# SF32LB56x register map
File version: 1.0
CPU: CM33 r0p1, little endian, MPU, FPU, 3 interrupt priority bits
Registers are 32-bit, read-write, reset 0x0 unless marked. A register's access mark holds for its fields unless they carry their own. Offsets are from the block's base; [hi:lo] are bit positions; {n}, {i} and the like mark numbered series; 'fields as' and 'values as' point back to an identical list.

## GPADC
Base 0x50016000
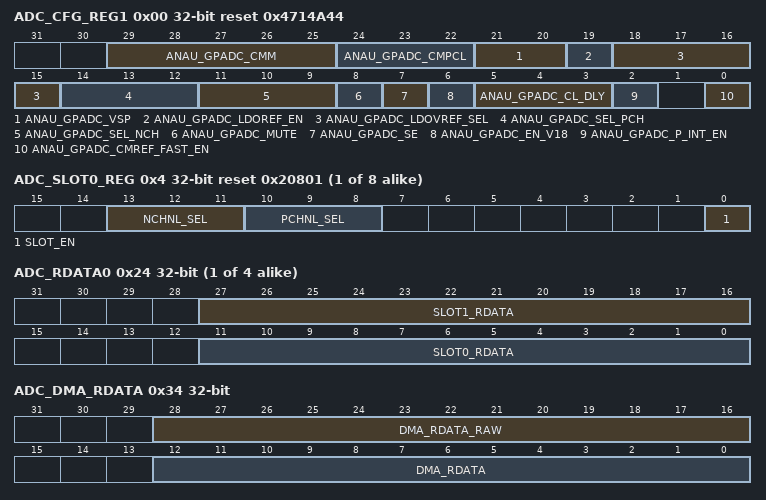
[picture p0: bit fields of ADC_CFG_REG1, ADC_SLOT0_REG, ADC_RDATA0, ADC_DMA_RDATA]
0x00 ADC_CFG_REG1 reset 0x4714A44 — ADC Analog Config Register 1
  [29:25] ANAU_GPADC_CMM — Tune CDAC CM voltage 375mV range (increasing) / 25mV step, 8: for 0.5V Vcm,in
  [24:22] ANAU_GPADC_CMPCL — Tune ADC comparator CL= 3: 40f, range: 10fF (0) ~ 80fF (7) / 10fF step
  [21:20] ANAU_GPADC_VSP — Set comparator input CM in sampling phase, 0.539V (0) / 0.578V (1) / 0.642V (2) / 0.784V (3)
  [19] ANAU_GPADC_LDOREF_EN — Enable LDORF for ADC VREF
  [18:15] ANAU_GPADC_LDOVREF_SEL — Set reference voltage for LDOREF, range = 0.35V(0) ~ 0.65V(15), step = 20mV
  [14:12] ANAU_GPADC_SEL_PCH — Select P-side input channel for GPADC, 0 for channel 0, 7 for channel 7, effective when force on
  [11:9] ANAU_GPADC_SEL_NCH — Select N-side input channel for GPADC, 0 for channel 0, 7 for channel 7, effective when force on
  [8] ANAU_GPADC_MUTE — Short GPADC P and N input to CMREF, i.e., VREF/2
  [7] ANAU_GPADC_SE — Set GPADC in single-ended mode, signal range at P-input: 0 ~ VREF
  [6] ANAU_GPADC_EN_V18
  [5:3] ANAU_GPADC_CL_DLY
  [2] ANAU_GPADC_P_INT_EN
  [0] ANAU_GPADC_CMREF_FAST_EN
{0x4+4i} ADC_SLOT{i}_REG reset 0x20801 (i=0..7) — ADC Slot{i} Config Register
  [13:11] NCHNL_SEL, [10:8] PCHNL_SEL, [0] SLOT_EN
{0x24+4i} ADC_RDATA{i} (i=0..3) — ADC Read Data{i}
  [27:16] SLOT{2i+1}_RDATA, [11:0] SLOT{2i}_RDATA
0x34 ADC_DMA_RDATA — ADC Read Data For DMA
  [28:16] DMA_RDATA_RAW, [12:0] DMA_RDATA
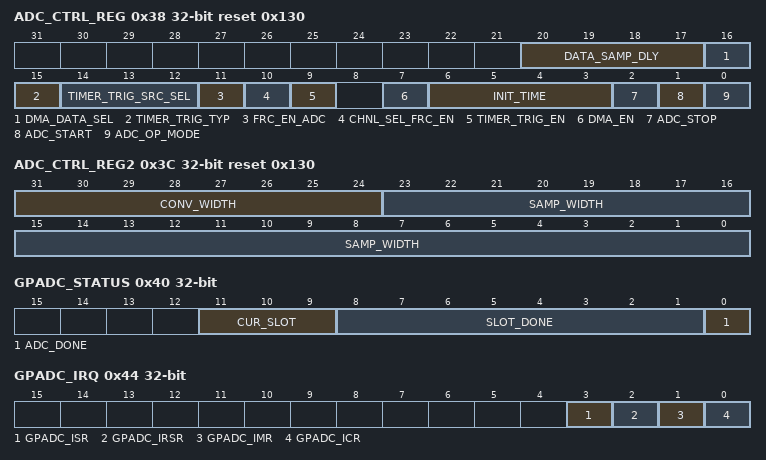
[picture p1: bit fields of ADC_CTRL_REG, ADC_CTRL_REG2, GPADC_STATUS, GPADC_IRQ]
0x38 ADC_CTRL_REG reset 0x130 — ADC Control Register
  [20:17] DATA_SAMP_DLY
  [16] DMA_DATA_SEL — 0: combined data 1: raw data
  [15] TIMER_TRIG_TYP — 0: pulse no edge detect needed 1: level,need edge detect
  [14:12] TIMER_TRIG_SRC_SEL — Timer trigger source select
  [11] FRC_EN_ADC — Enable GPADC core
  [10] CHNL_SEL_FRC_EN — Enable input channel setting in ADC_CFG_REG1
  [9] TIMER_TRIG_EN — Enable timer trigger function
  [7] DMA_EN — Enable DMA interface
  [6:3] INIT_TIME — GPADC will wait INIT_TIME ADCCLK cycles to start sample/conversion after being trigged
  [2] ADC_STOP — Write 1 to stop GPADC in continuous mode(need write 0 to clear)
  [1] ADC_START — Write 1 to start GPADC,(don't need clear )
  [0] ADC_OP_MODE — 0: single conversion mode 1: continuous conversion mode
0x3C ADC_CTRL_REG2 reset 0x130 — ADC Control Register2
  [31:24] CONV_WIDTH, [23:0] SAMP_WIDTH
0x40 GPADC_STATUS
  [11:9] CUR_SLOT, [8:1] SLOT_DONE, [0] ADC_DONE
0x44 GPADC_IRQ
  [3] GPADC_ISR, [2] GPADC_IRSR, [1] GPADC_IMR, [0] GPADC_ICR

## TSEN
Base 0x5001A000
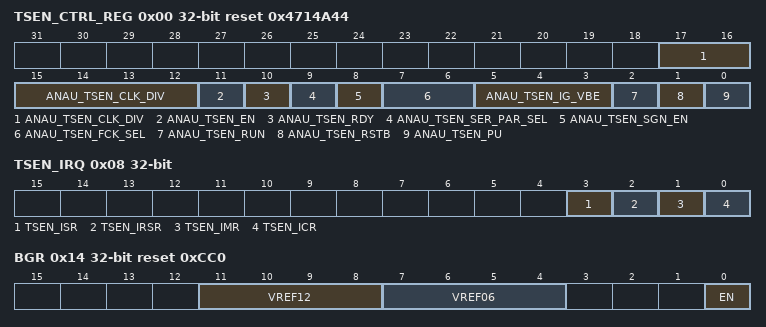
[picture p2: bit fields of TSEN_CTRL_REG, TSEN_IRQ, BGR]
0x00 TSEN_CTRL_REG reset 0x4714A44 — TSEN Analog Control Register
  [17:12] ANAU_TSEN_CLK_DIV — gen tsen clk by divide hclk by anau_tsen_clk_div
  [11] ANAU_TSEN_EN — Enable tsen digital module
  [10] ANAU_TSEN_RDY — tsen ready
  [9] ANAU_TSEN_SER_PAR_SEL — serial-parallel output selection
  [8] ANAU_TSEN_SGN_EN — signature-mode enable
  [7:6] ANAU_TSEN_FCK_SEL — select internal clock frequency
  [5:3] ANAU_TSEN_IG_VBE — bias current selection to tune vba
  [2] ANAU_TSEN_RUN — enable tsen run
  [1] ANAU_TSEN_RSTB — resetb for tsen
  [0] ANAU_TSEN_PU — power up tsen
0x04 TSEN_RDATA — Tsen Read Data
  [11:0] TSEN_RDATA
0x08 TSEN_IRQ
  [3] TSEN_ISR, [2] TSEN_IRSR, [1] TSEN_IMR, [0] TSEN_ICR
0x10 ANAU_ANA_TP — Tsen IRQ Register
  [0] ANAU_IARY_EN
0x14 BGR reset 0xCC0 — Bandgap registers
  [11:8] VREF12 — select VREF 1.2V
  [7:4] VREF06 — select VREF 0.6V
  [0] EN — Bandgap enable

## RTC
Base 0x5004B000
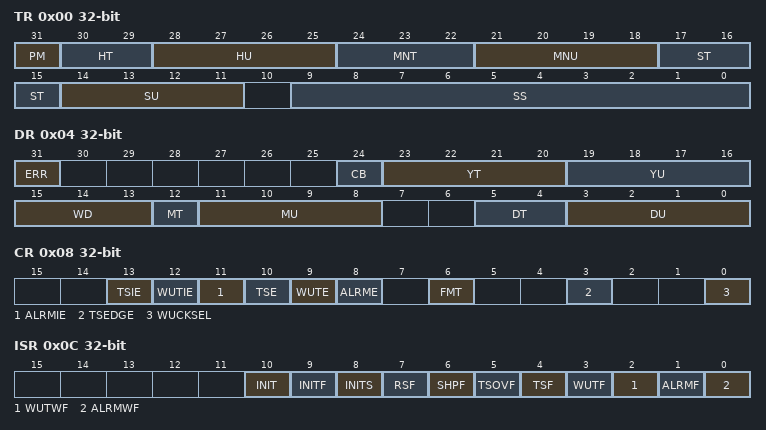
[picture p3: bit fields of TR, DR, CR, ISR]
0x00 TR — Time Register
  [31] PM, [30:29] HT, [28:25] HU, [24:22] MNT, [21:18] MNU, [17:15] ST, [14:11] SU, [9:0] SS
0x04 DR — Date Register
  [31] ERR
  [24] CB — century bit, 0 - 2000s, 1 - 1900s/2100s
  [23:20] YT
  [19:16] YU
  [15:13] WD
  [12] MT
  [11:8] MU
  [5:4] DT
  [3:0] DU
0x08 CR — Control Register
  [13] TSIE, [12] WUTIE, [11] ALRMIE, [10] TSE, [9] WUTE, [8] ALRME, [6] FMT, [3] TSEDGE, [0] WUCKSEL
0x0C ISR — Initialization and Status Register
  [10] INIT, [9] INITF, [8] INITS, [7] RSF, [6] SHPF, [5] TSOVF, [4] TSF, [3] WUTF, [2] WUTWF, [1] ALRMF, [0] ALRMWF
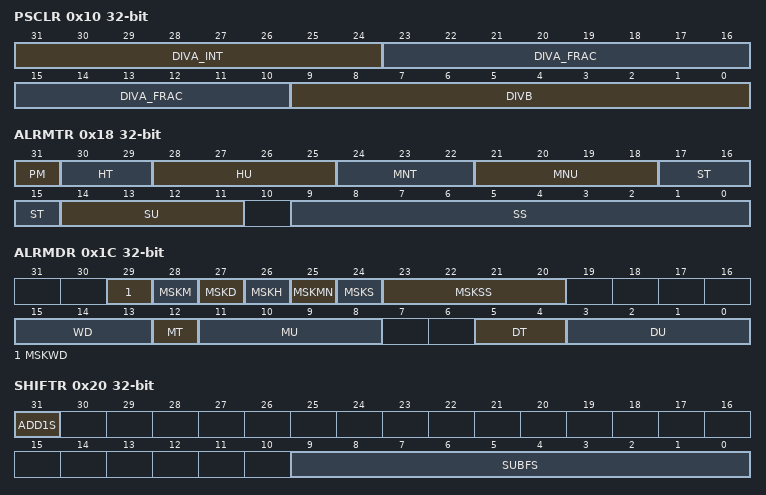
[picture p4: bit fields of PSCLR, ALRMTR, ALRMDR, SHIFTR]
0x10 PSCLR — Prescaler Register
  [31:24] DIVA_INT, [23:10] DIVA_FRAC, [9:0] DIVB
0x14 WUTR — Wakeup Timer Register
  [17:0] WUT
0x18 ALRMTR — Alarm Time Register
  fields as TR
0x1C ALRMDR — Alarm Date Register
  [29] MSKWD, [28] MSKM, [27] MSKD, [26] MSKH, [25] MSKMN, [24] MSKS, [23:20] MSKSS, [15:13] WD, [12] MT, [11:8] MU, [5:4] DT, [3:0] DU
0x20 SHIFTR — Shift Control Register
  [31] ADD1S, [9:0] SUBFS
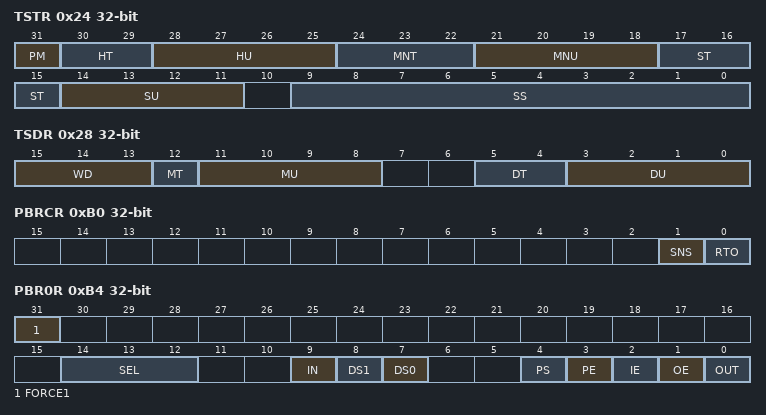
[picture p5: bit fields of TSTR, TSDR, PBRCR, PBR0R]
0x24 TSTR — Timestamp Time Register
  fields as TR
0x28 TSDR — Timestamp Date Register
  [15:13] WD, [12] MT, [11:8] MU, [5:4] DT, [3:0] DU
0x2C OR
{0x30+4i} BKP{i}R (i=0..31) — Backup {i} Register
  [31:0] BKP
0xB0 PBRCR — PBR Control Register
  [1] SNS, [0] RTO
0xB4 PBR0R — PBR0 Register
  [31] FORCE1 — special use. Set 1 to force output 1
  [14:12] SEL
  [9] IN
  [8] DS1
  [7] DS0
  [4] PS
  [3] PE
  [2] IE
  [1] OE
  [0] OUT
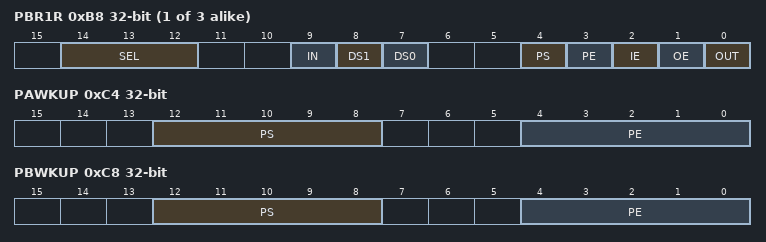
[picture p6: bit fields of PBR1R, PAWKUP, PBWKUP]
{0xB4+4i} PBR{i}R (i=1..3) — PBR{i} Register
  [14:12] SEL, [9] IN, [8] DS1, [7] DS0, [4] PS, [3] PE, [2] IE, [1] OE, [0] OUT
0xC4 PAWKUP — PA Wakeup Register
  [12:8] PS, [4:0] PE
0xC8 PBWKUP — PB Wakeup Register
  [12:8] PS
  [4:0] PE — Enable PB32 WKUP pull-down by default
